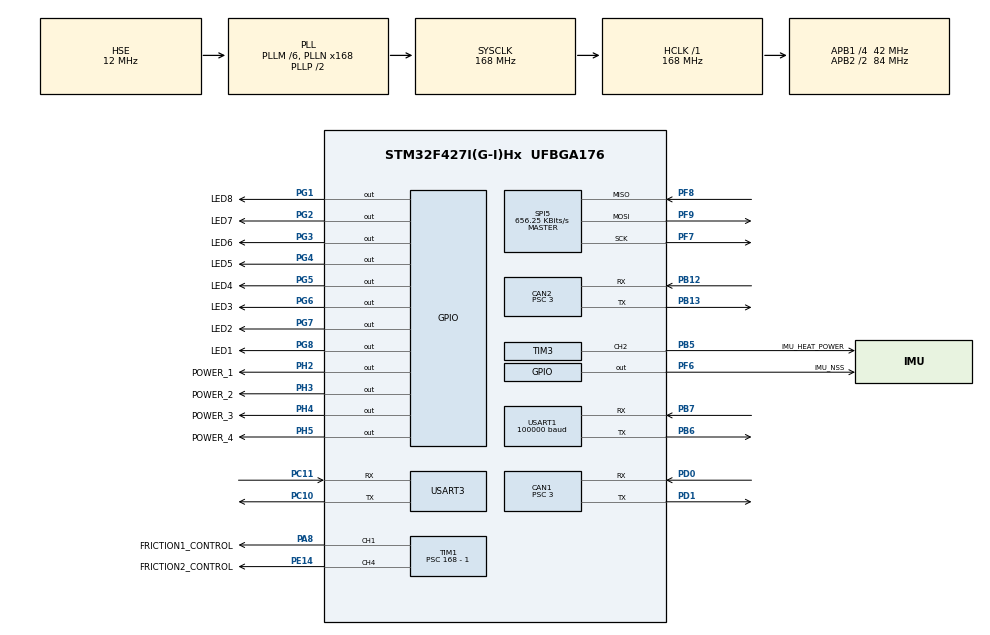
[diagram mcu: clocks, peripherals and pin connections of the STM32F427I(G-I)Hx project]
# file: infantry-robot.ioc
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CAN1.BS1=CAN_BS1_9TQ
CAN1.BS2=CAN_BS2_4TQ
CAN1.CalculateBaudRate=1000000
CAN1.CalculateTimeBit=999.99
CAN1.CalculateTimeQuantum=71.42857142857143
CAN1.NART=ENABLE
CAN1.Prescaler=3
CAN1.SJW=CAN_SJW_1TQ
CAN1.TXFP=ENABLE
CAN2.BS1=CAN_BS1_9TQ
CAN2.BS2=CAN_BS2_4TQ
CAN2.CalculateBaudRate=1000000
CAN2.CalculateTimeBit=999.99
CAN2.CalculateTimeQuantum=71.42857142857143
CAN2.NART=ENABLE
CAN2.Prescaler=3
CAN2.TXFP=ENABLE
Dma.Request0=USART1_RX
Dma.USART1_RX.0.Direction=DMA_PERIPH_TO_MEMORY
Dma.USART1_RX.0.FIFOMode=DMA_FIFOMODE_DISABLE
Dma.USART1_RX.0.Instance=DMA2_Stream2
Dma.USART1_RX.0.MemDataAlignment=DMA_MDATAALIGN_BYTE
Dma.USART1_RX.0.MemInc=DMA_MINC_ENABLE
Dma.USART1_RX.0.Mode=DMA_NORMAL
Dma.USART1_RX.0.PeriphDataAlignment=DMA_PDATAALIGN_BYTE
Dma.USART1_RX.0.PeriphInc=DMA_PINC_DISABLE
Dma.USART1_RX.0.Priority=DMA_PRIORITY_MEDIUM
FREERTOS.Tasks01=defaultTask,55,128,Default_Task,Default,NULL,Dynamic,NULL,NULL
FREERTOS.configENABLE_FPU=1
FREERTOS.configTIMER_TASK_PRIORITY=55
Mcu.Family=STM32F4
Mcu.Name=STM32F427I(G-I)Hx
Mcu.Package=UFBGA176
NVIC.CAN1_RX0_IRQn=true\:5\:0\:false\:false\:true\:true\:true\:true
NVIC.CAN1_SCE_IRQn=true\:5\:0\:false\:false\:true\:false\:true\:true
NVIC.CAN2_RX0_IRQn=true\:5\:0\:false\:false\:true\:false\:true\:true
NVIC.CAN2_SCE_IRQn=true\:5\:0\:false\:false\:true\:true\:true\:true
NVIC.DMA2_Stream2_IRQn=true\:5\:0\:false\:false\:true\:true\:false\:true
NVIC.PriorityGroup=NVIC_PRIORITYGROUP_4
NVIC.TIM6_DAC_IRQn=true\:0\:0\:false\:false\:true\:false\:false\:true
NVIC.TimeBase=TIM6_DAC_IRQn
NVIC.TimeBaseIP=TIM6
NVIC.USART1_IRQn=true\:5\:0\:false\:false\:true\:true\:true\:true
NVIC.USART3_IRQn=true\:5\:0\:false\:false\:true\:true\:true\:true
PA13.Mode=Trace_Asynchronous_SW
PA13.Signal=SYS_JTMS-SWDIO
PA14.Mode=Trace_Asynchronous_SW
PA14.Signal=SYS_JTCK-SWCLK
PA8.GPIO_Label=FRICTION1_CONTROL
PA8.Signal=S_TIM1_CH1
PB12.Mode=CAN_Activate
PB12.Signal=CAN2_RX
PB13.Mode=CAN_Activate
PB13.Signal=CAN2_TX
PB3.Mode=Trace_Asynchronous_SW
PB3.Signal=SYS_JTDO-SWO
PB5.GPIO_Label=IMU_HEAT_POWER
PB5.Signal=S_TIM3_CH2
PB6.Mode=Asynchronous
PB6.Signal=USART1_TX
PB7.Mode=Asynchronous
PB7.Signal=USART1_RX
PC10.Mode=Asynchronous
PC10.Signal=USART3_TX
PC11.Mode=Asynchronous
PC11.Signal=USART3_RX
PD0.Mode=CAN_Activate
PD0.Signal=CAN1_RX
PD1.Mode=CAN_Activate
PD1.Signal=CAN1_TX
PE14.GPIO_Label=FRICTION2_CONTROL
PE14.Signal=S_TIM1_CH4
PF6.GPIO_Label=IMU_NSS
PF6.PinState=GPIO_PIN_SET
PF6.Signal=GPIO_Output
PF7.Mode=Full_Duplex_Master
PF7.Signal=SPI5_SCK
PF8.Mode=Full_Duplex_Master
PF8.Signal=SPI5_MISO
PF9.Mode=Full_Duplex_Master
PF9.Signal=SPI5_MOSI
PG1.GPIO_Label=LED8
PG1.PinState=GPIO_PIN_SET
PG1.Signal=GPIO_Output
PG2.GPIO_Label=LED7
PG2.PinState=GPIO_PIN_SET
PG2.Signal=GPIO_Output
PG3.GPIO_Label=LED6
PG3.PinState=GPIO_PIN_SET
PG3.Signal=GPIO_Output
PG4.GPIO_Label=LED5
PG4.PinState=GPIO_PIN_SET
PG4.Signal=GPIO_Output
PG5.GPIO_Label=LED4
PG5.PinState=GPIO_PIN_SET
PG5.Signal=GPIO_Output
PG6.GPIO_Label=LED3
PG6.PinState=GPIO_PIN_SET
PG6.Signal=GPIO_Output
PG7.GPIO_Label=LED2
PG7.PinState=GPIO_PIN_SET
PG7.Signal=GPIO_Output
PG8.GPIO_Label=LED1
PG8.PinState=GPIO_PIN_SET
PG8.Signal=GPIO_Output
PH0/OSC_IN.Mode=HSE-External-Oscillator
PH0/OSC_IN.Signal=RCC_OSC_IN
PH1/OSC_OUT.Mode=HSE-External-Oscillator
PH1/OSC_OUT.Signal=RCC_OSC_OUT
PH2.GPIO_Label=POWER_1
PH2.PinState=GPIO_PIN_SET
PH2.Signal=GPIO_Output
PH3.GPIO_Label=POWER_2
PH3.PinState=GPIO_PIN_SET
PH3.Signal=GPIO_Output
PH4.GPIO_Label=POWER_3
PH4.PinState=GPIO_PIN_SET
PH4.Signal=GPIO_Output
PH5.GPIO_Label=POWER_4
PH5.PinState=GPIO_PIN_SET
PH5.Signal=GPIO_Output
ProjectManager.HeapSize=0x200
ProjectManager.StackSize=0x400
ProjectManager.TargetToolchain=STM32CubeIDE
RCC.48MHZClocksFreq_Value=48000000
RCC.AHBFreq_Value=168000000
RCC.APB1CLKDivider=RCC_HCLK_DIV4
RCC.APB1Freq_Value=42000000
RCC.APB1TimFreq_Value=84000000
RCC.APB2CLKDivider=RCC_HCLK_DIV2
RCC.APB2Freq_Value=84000000
RCC.APB2TimFreq_Value=168000000
RCC.CortexFreq_Value=168000000
RCC.EnbaleCSS=true
RCC.HCLKFreq_Value=168000000
RCC.HSE_VALUE=12000000
RCC.HSI_VALUE=16000000
RCC.LSE_VALUE=32768
RCC.PLLM=6
RCC.PLLN=168
RCC.PLLQ=7
RCC.PLLSourceVirtual=RCC_PLLSOURCE_HSE
RCC.SYSCLKFreq_VALUE=168000000
RCC.SYSCLKSource=RCC_SYSCLKSOURCE_PLLCLK
RCC.VCOOutputFreq_Value=336000000
SH.S_TIM1_CH1.0=TIM1_CH1,PWM Generation1 CH1
SH.S_TIM1_CH4.0=TIM1_CH4,PWM Generation4 CH4
SH.S_TIM3_CH2.0=TIM3_CH2,PWM Generation2 CH2
SPI5.BaudRatePrescaler=SPI_BAUDRATEPRESCALER_128
SPI5.CalculateBaudRate=656.25 KBits/s
SPI5.Direction=SPI_DIRECTION_2LINES
SPI5.Mode=SPI_MODE_MASTER
SPI5.VirtualType=VM_MASTER
TIM1.AutoReloadPreload=TIM_AUTORELOAD_PRELOAD_ENABLE
TIM1.Channel-PWM\ Generation1\ CH1=TIM_CHANNEL_1
TIM1.Channel-PWM\ Generation4\ CH4=TIM_CHANNEL_4
TIM1.ClockDivision=TIM_CLOCKDIVISION_DIV1
TIM1.OCIdleState_1=TIM_OCIDLESTATE_SET
TIM1.OCIdleState_4=TIM_OCIDLESTATE_SET
TIM1.OCPolarity_1=TIM_OCPOLARITY_HIGH
TIM1.OCPolarity_4=TIM_OCPOLARITY_HIGH
TIM1.Period=2000 - 1
TIM1.Prescaler=168 - 1
TIM1.Pulse-PWM\ Generation1\ CH1=0
TIM1.Pulse-PWM\ Generation4\ CH4=0
TIM3.AutoReloadPreload=TIM_AUTORELOAD_PRELOAD_ENABLE
TIM3.Channel-PWM\ Generation2\ CH2=TIM_CHANNEL_2
TIM3.Period=1000 - 1
TIM3.Prescaler=168-1
USART1.BaudRate=100000
USART1.Mode=MODE_RX
USART1.OverSampling=UART_OVERSAMPLING_16
USART1.Parity=PARITY_EVEN
USART1.VirtualMode=VM_ASYNC
USART1.WordLength=WORDLENGTH_9B
USART3.VirtualMode=VM_ASYNC
VP_FREERTOS_VS_CMSIS_V2.Mode=CMSIS_V2
VP_SYS_VS_tim6.Mode=TIM6
VP_TIM1_VS_ClockSourceINT.Mode=Internal
VP_TIM3_VS_ClockSourceINT.Mode=Internal
board=custom

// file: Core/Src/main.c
/* USER CODE BEGIN Header */
/**
  ******************************************************************************
  * @file           : main.c
  * @brief          : Main program body
  ******************************************************************************
  * @attention
  *
  * <h2><center>&copy; Copyright (c) 2020 STMicroelectronics.
  * All rights reserved.</center></h2>
  *
  * This software component is licensed by ST under BSD 3-Clause license,
  * the "License"; You may not use this file except in compliance with the
  * License. You may obtain a copy of the License at:
  *                        opensource.org/licenses/BSD-3-Clause
  *
  ******************************************************************************
  */
/* USER CODE END Header */
#include "main.h"
#include "cmsis_os.h"

/* USER CODE BEGIN Includes */
#include "Library/Inc/tool.h"
#include "tasks/entry.h"
/* USER CODE END Includes */

CAN_HandleTypeDef hcan1;
CAN_HandleTypeDef hcan2;

SPI_HandleTypeDef hspi5;

TIM_HandleTypeDef htim1;
TIM_HandleTypeDef htim3;

UART_HandleTypeDef huart1;
UART_HandleTypeDef huart3;
DMA_HandleTypeDef hdma_usart1_rx;

/* Definitions for defaultTask */
osThreadId_t defaultTaskHandle;
const osThreadAttr_t defaultTask_attributes = {
  .name = "defaultTask",
  .priority = (osPriority_t) osPriorityRealtime7,
  .stack_size = 128 * 4
};

void SystemClock_Config(void);
static void MX_GPIO_Init(void);
static void MX_DMA_Init(void);
static void MX_CAN1_Init(void);
static void MX_CAN2_Init(void);
static void MX_SPI5_Init(void);
static void MX_USART1_UART_Init(void);
static void MX_TIM3_Init(void);
static void MX_USART3_UART_Init(void);
static void MX_TIM1_Init(void);
void Default_Task(void *argument);

int main(void)
{

  /* MCU Configuration--------------------------------------------------------*/

  /* Reset of all peripherals, Initializes the Flash interface and the Systick. */
  HAL_Init();

  /* Configure the system clock */
  SystemClock_Config();

  /* Initialize all configured peripherals */
  MX_GPIO_Init();
  MX_DMA_Init();
  MX_CAN1_Init();
  MX_CAN2_Init();
  MX_SPI5_Init();
  MX_USART1_UART_Init();
  MX_TIM3_Init();
  MX_USART3_UART_Init();
  MX_TIM1_Init();

  /* Init scheduler */
  osKernelInitialize();

  /* Create the thread(s) */
  /* creation of defaultTask */
  defaultTaskHandle = osThreadNew(Default_Task, NULL, &defaultTask_attributes);

  /* Start scheduler */
  osKernelStart();

  /* We should never get here as control is now taken by the scheduler */
  /* Infinite loop */
  while (1)
  {

  }
}

void SystemClock_Config(void)
{
  RCC_OscInitTypeDef RCC_OscInitStruct = {0};
  RCC_ClkInitTypeDef RCC_ClkInitStruct = {0};

  /** Configure the main internal regulator output voltage
  */
  __HAL_RCC_PWR_CLK_ENABLE();
  __HAL_PWR_VOLTAGESCALING_CONFIG(PWR_REGULATOR_VOLTAGE_SCALE1);
  /** Initializes the RCC Oscillators according to the specified parameters
  * in the RCC_OscInitTypeDef structure.
  */
  RCC_OscInitStruct.OscillatorType = RCC_OSCILLATORTYPE_HSE;
  RCC_OscInitStruct.HSEState = RCC_HSE_ON;
  RCC_OscInitStruct.PLL.PLLState = RCC_PLL_ON;
  RCC_OscInitStruct.PLL.PLLSource = RCC_PLLSOURCE_HSE;
  RCC_OscInitStruct.PLL.PLLM = 6;
  RCC_OscInitStruct.PLL.PLLN = 168;
  RCC_OscInitStruct.PLL.PLLP = RCC_PLLP_DIV2;
  RCC_OscInitStruct.PLL.PLLQ = 7;
  if (HAL_RCC_OscConfig(&RCC_OscInitStruct) != HAL_OK)
  {
    Error_Handler();
  }
  /** Initializes the CPU, AHB and APB buses clocks
  */
  RCC_ClkInitStruct.ClockType = RCC_CLOCKTYPE_HCLK|RCC_CLOCKTYPE_SYSCLK
                              |RCC_CLOCKTYPE_PCLK1|RCC_CLOCKTYPE_PCLK2;
  RCC_ClkInitStruct.SYSCLKSource = RCC_SYSCLKSOURCE_PLLCLK;
  RCC_ClkInitStruct.AHBCLKDivider = RCC_SYSCLK_DIV1;
  RCC_ClkInitStruct.APB1CLKDivider = RCC_HCLK_DIV4;
  RCC_ClkInitStruct.APB2CLKDivider = RCC_HCLK_DIV2;

  if (HAL_RCC_ClockConfig(&RCC_ClkInitStruct, FLASH_LATENCY_5) != HAL_OK)
  {
    Error_Handler();
  }
  /** Enables the Clock Security System
  */
  HAL_RCC_EnableCSS();
}

static void MX_CAN1_Init(void)
{

  hcan1.Instance = CAN1;
  hcan1.Init.Prescaler = 3;
  hcan1.Init.Mode = CAN_MODE_NORMAL;
  hcan1.Init.SyncJumpWidth = CAN_SJW_1TQ;
  hcan1.Init.TimeSeg1 = CAN_BS1_9TQ;
  hcan1.Init.TimeSeg2 = CAN_BS2_4TQ;
  hcan1.Init.TimeTriggeredMode = DISABLE;
  hcan1.Init.AutoBusOff = DISABLE;
  hcan1.Init.AutoWakeUp = DISABLE;
  hcan1.Init.AutoRetransmission = ENABLE;
  hcan1.Init.ReceiveFifoLocked = DISABLE;
  hcan1.Init.TransmitFifoPriority = ENABLE;
  if (HAL_CAN_Init(&hcan1) != HAL_OK)
  {
    Error_Handler();
  }

}

static void MX_CAN2_Init(void)
{

  hcan2.Instance = CAN2;
  hcan2.Init.Prescaler = 3;
  hcan2.Init.Mode = CAN_MODE_NORMAL;
  hcan2.Init.SyncJumpWidth = CAN_SJW_1TQ;
  hcan2.Init.TimeSeg1 = CAN_BS1_9TQ;
  hcan2.Init.TimeSeg2 = CAN_BS2_4TQ;
  hcan2.Init.TimeTriggeredMode = DISABLE;
  hcan2.Init.AutoBusOff = DISABLE;
  hcan2.Init.AutoWakeUp = DISABLE;
  hcan2.Init.AutoRetransmission = ENABLE;
  hcan2.Init.ReceiveFifoLocked = DISABLE;
  hcan2.Init.TransmitFifoPriority = ENABLE;
  if (HAL_CAN_Init(&hcan2) != HAL_OK)
  {
    Error_Handler();
  }

}

static void MX_SPI5_Init(void)
{

  /* SPI5 parameter configuration*/
  hspi5.Instance = SPI5;
  hspi5.Init.Mode = SPI_MODE_MASTER;
  hspi5.Init.Direction = SPI_DIRECTION_2LINES;
  hspi5.Init.DataSize = SPI_DATASIZE_8BIT;
  hspi5.Init.CLKPolarity = SPI_POLARITY_LOW;
  hspi5.Init.CLKPhase = SPI_PHASE_1EDGE;
  hspi5.Init.NSS = SPI_NSS_SOFT;
  hspi5.Init.BaudRatePrescaler = SPI_BAUDRATEPRESCALER_128;
  hspi5.Init.FirstBit = SPI_FIRSTBIT_MSB;
  hspi5.Init.TIMode = SPI_TIMODE_DISABLE;
  hspi5.Init.CRCCalculation = SPI_CRCCALCULATION_DISABLE;
  hspi5.Init.CRCPolynomial = 10;
  if (HAL_SPI_Init(&hspi5) != HAL_OK)
  {
    Error_Handler();
  }

}

static void MX_TIM1_Init(void)
{

  TIM_ClockConfigTypeDef sClockSourceConfig = {0};
  TIM_MasterConfigTypeDef sMasterConfig = {0};
  TIM_OC_InitTypeDef sConfigOC = {0};
  TIM_BreakDeadTimeConfigTypeDef sBreakDeadTimeConfig = {0};

  htim1.Instance = TIM1;
  htim1.Init.Prescaler = 168 - 1;
  htim1.Init.CounterMode = TIM_COUNTERMODE_UP;
  htim1.Init.Period = 2000 - 1;
  htim1.Init.ClockDivision = TIM_CLOCKDIVISION_DIV1;
  htim1.Init.RepetitionCounter = 0;
  htim1.Init.AutoReloadPreload = TIM_AUTORELOAD_PRELOAD_ENABLE;
  if (HAL_TIM_Base_Init(&htim1) != HAL_OK)
  {
    Error_Handler();
  }
  sClockSourceConfig.ClockSource = TIM_CLOCKSOURCE_INTERNAL;
  if (HAL_TIM_ConfigClockSource(&htim1, &sClockSourceConfig) != HAL_OK)
  {
    Error_Handler();
  }
  if (HAL_TIM_PWM_Init(&htim1) != HAL_OK)
  {
    Error_Handler();
  }
  sMasterConfig.MasterOutputTrigger = TIM_TRGO_RESET;
  sMasterConfig.MasterSlaveMode = TIM_MASTERSLAVEMODE_DISABLE;
  if (HAL_TIMEx_MasterConfigSynchronization(&htim1, &sMasterConfig) != HAL_OK)
  {
    Error_Handler();
  }
  sConfigOC.OCMode = TIM_OCMODE_PWM1;
  sConfigOC.Pulse = 0;
  sConfigOC.OCPolarity = TIM_OCPOLARITY_HIGH;
  sConfigOC.OCNPolarity = TIM_OCNPOLARITY_HIGH;
  sConfigOC.OCFastMode = TIM_OCFAST_DISABLE;
  sConfigOC.OCIdleState = TIM_OCIDLESTATE_SET;
  sConfigOC.OCNIdleState = TIM_OCNIDLESTATE_RESET;
  if (HAL_TIM_PWM_ConfigChannel(&htim1, &sConfigOC, TIM_CHANNEL_1) != HAL_OK)
  {
    Error_Handler();
  }
  if (HAL_TIM_PWM_ConfigChannel(&htim1, &sConfigOC, TIM_CHANNEL_4) != HAL_OK)
  {
    Error_Handler();
  }
  sBreakDeadTimeConfig.OffStateRunMode = TIM_OSSR_DISABLE;
  sBreakDeadTimeConfig.OffStateIDLEMode = TIM_OSSI_DISABLE;
  sBreakDeadTimeConfig.LockLevel = TIM_LOCKLEVEL_OFF;
  sBreakDeadTimeConfig.DeadTime = 0;
  sBreakDeadTimeConfig.BreakState = TIM_BREAK_DISABLE;
  sBreakDeadTimeConfig.BreakPolarity = TIM_BREAKPOLARITY_HIGH;
  sBreakDeadTimeConfig.AutomaticOutput = TIM_AUTOMATICOUTPUT_DISABLE;
  if (HAL_TIMEx_ConfigBreakDeadTime(&htim1, &sBreakDeadTimeConfig) != HAL_OK)
  {
    Error_Handler();
  }
  HAL_TIM_MspPostInit(&htim1);

}

static void MX_TIM3_Init(void)
{

  TIM_ClockConfigTypeDef sClockSourceConfig = {0};
  TIM_MasterConfigTypeDef sMasterConfig = {0};
  TIM_OC_InitTypeDef sConfigOC = {0};

  htim3.Instance = TIM3;
  htim3.Init.Prescaler = 168-1;
  htim3.Init.CounterMode = TIM_COUNTERMODE_UP;
  htim3.Init.Period = 1000 - 1;
  htim3.Init.ClockDivision = TIM_CLOCKDIVISION_DIV1;
  htim3.Init.AutoReloadPreload = TIM_AUTORELOAD_PRELOAD_ENABLE;
  if (HAL_TIM_Base_Init(&htim3) != HAL_OK)
  {
    Error_Handler();
  }
  sClockSourceConfig.ClockSource = TIM_CLOCKSOURCE_INTERNAL;
  if (HAL_TIM_ConfigClockSource(&htim3, &sClockSourceConfig) != HAL_OK)
  {
    Error_Handler();
  }
  if (HAL_TIM_PWM_Init(&htim3) != HAL_OK)
  {
    Error_Handler();
  }
  sMasterConfig.MasterOutputTrigger = TIM_TRGO_RESET;
  sMasterConfig.MasterSlaveMode = TIM_MASTERSLAVEMODE_DISABLE;
  if (HAL_TIMEx_MasterConfigSynchronization(&htim3, &sMasterConfig) != HAL_OK)
  {
    Error_Handler();
  }
  sConfigOC.OCMode = TIM_OCMODE_PWM1;
  sConfigOC.Pulse = 0;
  sConfigOC.OCPolarity = TIM_OCPOLARITY_HIGH;
  sConfigOC.OCFastMode = TIM_OCFAST_DISABLE;
  if (HAL_TIM_PWM_ConfigChannel(&htim3, &sConfigOC, TIM_CHANNEL_2) != HAL_OK)
  {
    Error_Handler();
  }
  HAL_TIM_MspPostInit(&htim3);

}

static void MX_USART1_UART_Init(void)
{

  huart1.Instance = USART1;
  huart1.Init.BaudRate = 100000;
  huart1.Init.WordLength = UART_WORDLENGTH_9B;
  huart1.Init.StopBits = UART_STOPBITS_1;
  huart1.Init.Parity = UART_PARITY_EVEN;
  huart1.Init.Mode = UART_MODE_RX;
  huart1.Init.HwFlowCtl = UART_HWCONTROL_NONE;
  huart1.Init.OverSampling = UART_OVERSAMPLING_16;
  if (HAL_UART_Init(&huart1) != HAL_OK)
  {
    Error_Handler();
  }

}

static void MX_USART3_UART_Init(void)
{

  huart3.Instance = USART3;
  huart3.Init.BaudRate = 115200;
  huart3.Init.WordLength = UART_WORDLENGTH_8B;
  huart3.Init.StopBits = UART_STOPBITS_1;
  huart3.Init.Parity = UART_PARITY_NONE;
  huart3.Init.Mode = UART_MODE_TX_RX;
  huart3.Init.HwFlowCtl = UART_HWCONTROL_NONE;
  huart3.Init.OverSampling = UART_OVERSAMPLING_16;
  if (HAL_UART_Init(&huart3) != HAL_OK)
  {
    Error_Handler();
  }

}

static void MX_DMA_Init(void)
{

  /* DMA controller clock enable */
  __HAL_RCC_DMA2_CLK_ENABLE();

  /* DMA interrupt init */
  /* DMA2_Stream2_IRQn interrupt configuration */
  HAL_NVIC_SetPriority(DMA2_Stream2_IRQn, 5, 0);
  HAL_NVIC_EnableIRQ(DMA2_Stream2_IRQn);

}

static void MX_GPIO_Init(void)
{
  GPIO_InitTypeDef GPIO_InitStruct = {0};

  /* GPIO Ports Clock Enable */
  __HAL_RCC_GPIOB_CLK_ENABLE();
  __HAL_RCC_GPIOA_CLK_ENABLE();
  __HAL_RCC_GPIOD_CLK_ENABLE();
  __HAL_RCC_GPIOC_CLK_ENABLE();
  __HAL_RCC_GPIOH_CLK_ENABLE();
  __HAL_RCC_GPIOG_CLK_ENABLE();
  __HAL_RCC_GPIOF_CLK_ENABLE();
  __HAL_RCC_GPIOE_CLK_ENABLE();

  /*Configure GPIO pin Output Level */
  HAL_GPIO_WritePin(GPIOH, POWER_1_Pin|POWER_2_Pin|POWER_3_Pin|POWER_4_Pin, GPIO_PIN_SET);

  /*Configure GPIO pin Output Level */
  HAL_GPIO_WritePin(GPIOG, LED1_Pin|LED2_Pin|LED3_Pin|LED4_Pin
                          |LED5_Pin|LED6_Pin|LED7_Pin|LED8_Pin, GPIO_PIN_SET);

  /*Configure GPIO pin Output Level */
  HAL_GPIO_WritePin(IMU_NSS_GPIO_Port, IMU_NSS_Pin, GPIO_PIN_SET);

  /*Configure GPIO pins : POWER_1_Pin POWER_2_Pin POWER_3_Pin POWER_4_Pin */
  GPIO_InitStruct.Pin = POWER_1_Pin|POWER_2_Pin|POWER_3_Pin|POWER_4_Pin;
  GPIO_InitStruct.Mode = GPIO_MODE_OUTPUT_PP;
  GPIO_InitStruct.Pull = GPIO_NOPULL;
  GPIO_InitStruct.Speed = GPIO_SPEED_FREQ_LOW;
  HAL_GPIO_Init(GPIOH, &GPIO_InitStruct);

  /*Configure GPIO pins : LED1_Pin LED2_Pin LED3_Pin LED4_Pin
                           LED5_Pin LED6_Pin LED7_Pin LED8_Pin */
  GPIO_InitStruct.Pin = LED1_Pin|LED2_Pin|LED3_Pin|LED4_Pin
                          |LED5_Pin|LED6_Pin|LED7_Pin|LED8_Pin;
  GPIO_InitStruct.Mode = GPIO_MODE_OUTPUT_PP;
  GPIO_InitStruct.Pull = GPIO_NOPULL;
  GPIO_InitStruct.Speed = GPIO_SPEED_FREQ_LOW;
  HAL_GPIO_Init(GPIOG, &GPIO_InitStruct);

  /*Configure GPIO pin : IMU_NSS_Pin */
  GPIO_InitStruct.Pin = IMU_NSS_Pin;
  GPIO_InitStruct.Mode = GPIO_MODE_OUTPUT_PP;
  GPIO_InitStruct.Pull = GPIO_NOPULL;
  GPIO_InitStruct.Speed = GPIO_SPEED_FREQ_LOW;
  HAL_GPIO_Init(IMU_NSS_GPIO_Port, &GPIO_InitStruct);

}

void Default_Task(void *argument)
{
  /* USER CODE BEGIN 5 */
  Entry_Task();
  /* USER CODE END 5 */
}

 /**
  * @brief  Period elapsed callback in non blocking mode
  * @note   This function is called  when TIM6 interrupt took place, inside
  * HAL_TIM_IRQHandler(). It makes a direct call to HAL_IncTick() to increment
  * a global variable "uwTick" used as application time base.
  * @param  htim : TIM handle
  * @retval None
  */
void HAL_TIM_PeriodElapsedCallback(TIM_HandleTypeDef *htim)
{
  if (htim->Instance == TIM6) {
    HAL_IncTick();
  }
}

void Error_Handler(void)
{
}

/************************ (C) COPYRIGHT STMicroelectronics *****END OF FILE****/
